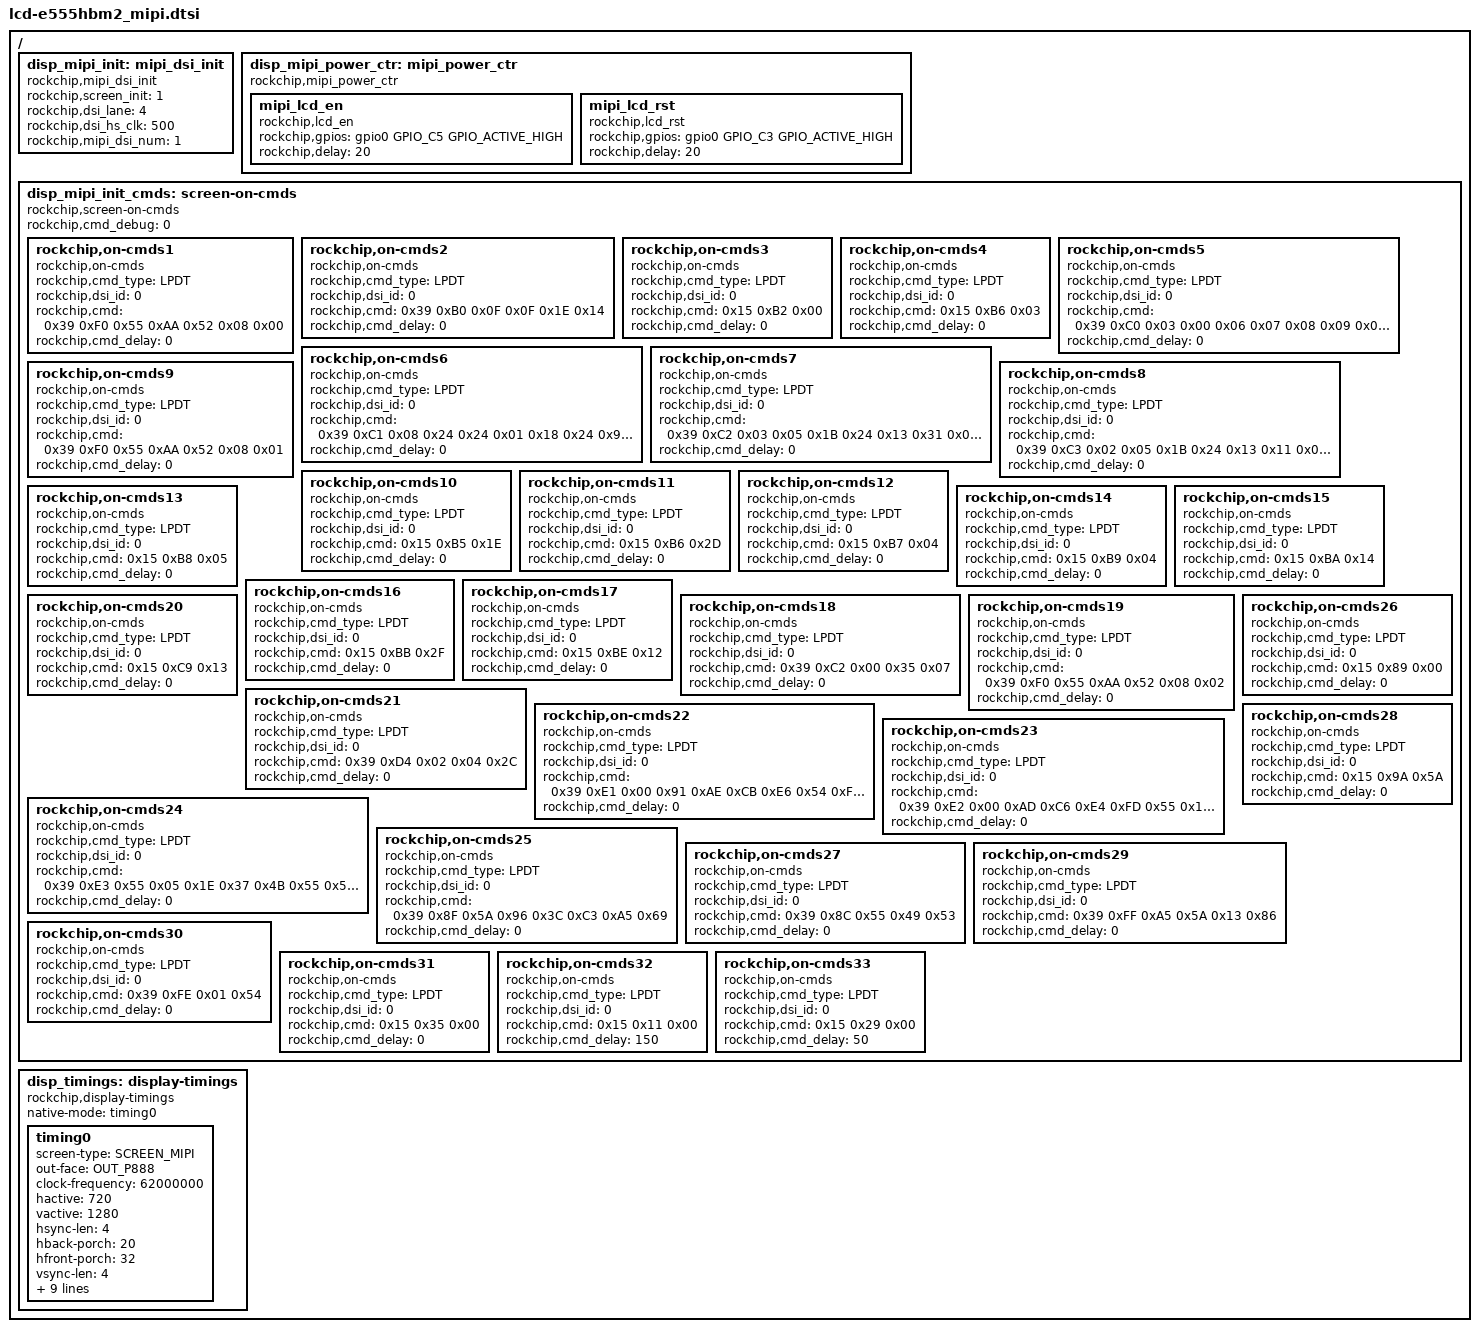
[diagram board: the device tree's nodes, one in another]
/*
 * Copyright (c) 2016 Fuzhou Rockchip Electronics Co., Ltd
 *
 * This file is dual-licensed: you can use it either under the terms
 * of the GPL or the X11 license, at your option. Note that this dual
 * licensing only applies to this file, and not this project as a
 * whole.
 *
 *  a) This file is free software; you can redistribute it and/or
 *     modify it under the terms of the GNU General Public License as
 *     published by the Free Software Foundation; either version 2 of the
 *     License, or (at your option) any later version.
 *
 *     This file is distributed in the hope that it will be useful,
 *     but WITHOUT ANY WARRANTY; without even the implied warranty of
 *     MERCHANTABILITY or FITNESS FOR A PARTICULAR PURPOSE.  See the
 *     GNU General Public License for more details.
 *
 * Or, alternatively,
 *
 *  b) Permission is hereby granted, free of charge, to any person
 *     obtaining a copy of this software and associated documentation
 *     files (the "Software"), to deal in the Software without
 *     restriction, including without limitation the rights to use,
 *     copy, modify, merge, publish, distribute, sublicense, and/or
 *     sell copies of the Software, and to permit persons to whom the
 *     Software is furnished to do so, subject to the following
 *     conditions:
 *
 *     The above copyright notice and this permission notice shall be
 *     included in all copies or substantial portions of the Software.
 *
 *     THE SOFTWARE IS PROVIDED "AS IS", WITHOUT WARRANTY OF ANY KIND,
 *     EXPRESS OR IMPLIED, INCLUDING BUT NOT LIMITED TO THE WARRANTIES
 *     OF MERCHANTABILITY, FITNESS FOR A PARTICULAR PURPOSE AND
 *     NONINFRINGEMENT. IN NO EVENT SHALL THE AUTHORS OR COPYRIGHT
 *     HOLDERS BE LIABLE FOR ANY CLAIM, DAMAGES OR OTHER LIABILITY,
 *     WHETHER IN AN ACTION OF CONTRACT, TORT OR OTHERWISE, ARISING
 *     FROM, OUT OF OR IN CONNECTION WITH THE SOFTWARE OR THE USE OR
 *     OTHER DEALINGS IN THE SOFTWARE.
 *
 * arch/arm/boot/dts/lcd_e555hbm2_mipi.dtsi
 * author: linjh@rock-chips.com
 * create date: 2016-10-26
 * lcd model: e555hbm2
 * resolution: 720 * 1280
 * mipi channel: single
 */

/ {
	/* about mipi */
	disp_mipi_init: mipi_dsi_init{
		compatible = "rockchip,mipi_dsi_init";
		rockchip,screen_init	= <1>;
		rockchip,dsi_lane	= <4>;
		rockchip,dsi_hs_clk	= <500>;
		rockchip,mipi_dsi_num	= <1>;
	};

	disp_mipi_power_ctr: mipi_power_ctr {
		compatible = "rockchip,mipi_power_ctr";
		mipi_lcd_en: mipi_lcd_en{
			compatible = "rockchip,lcd_en";
			rockchip,gpios = <&gpio0 GPIO_C5 GPIO_ACTIVE_HIGH>;
			rockchip,delay = <20>;
		};
		mipi_lcd_rst: mipi_lcd_rst{
			compatible = "rockchip,lcd_rst";
			rockchip,gpios = <&gpio0 GPIO_C3 GPIO_ACTIVE_HIGH>;
			rockchip,delay = <20>;
		};
	};

	disp_mipi_init_cmds: screen-on-cmds {
		rockchip,cmd_debug = <0>;
		compatible = "rockchip,screen-on-cmds";
		rockchip,on-cmds1 {
			compatible = "rockchip,on-cmds";
			rockchip,cmd_type = <LPDT>;
			rockchip,dsi_id = <0>;
			rockchip,cmd = <0x39 0xF0 0x55 0xAA 0x52 0x08 0x00>;
			rockchip,cmd_delay = <0>;
		};
		rockchip,on-cmds2 {
			compatible = "rockchip,on-cmds";
			rockchip,cmd_type = <LPDT>;
			rockchip,dsi_id = <0>;
			rockchip,cmd = <0x39 0xB0 0x0F 0x0F 0x1E 0x14>;
			rockchip,cmd_delay = <0>;
		};
		rockchip,on-cmds3 {
			compatible = "rockchip,on-cmds";
			rockchip,cmd_type = <LPDT>;
			rockchip,dsi_id = <0>;
			rockchip,cmd = <0x15 0xB2 0x00>;
			rockchip,cmd_delay = <0>;
		};
		rockchip,on-cmds4 {
			compatible = "rockchip,on-cmds";
			rockchip,cmd_type = <LPDT>;
			rockchip,dsi_id = <0>;
			rockchip,cmd = <0x15 0xB6 0x03>;
			rockchip,cmd_delay = <0>;
		};
		rockchip,on-cmds5 {
			compatible = "rockchip,on-cmds";
			rockchip,cmd_type = <LPDT>;
			rockchip,dsi_id = <0>;
			rockchip,cmd = <0x39 0xC0 0x03 0x00 0x06 0x07 0x08 0x09 0x00 0x00 0x00 0x00 0x02 0x00 0x0A 0x0B 0x0C 0x0D 0x00 0x00 0x00 0x00>;
			rockchip,cmd_delay = <0>;
		};
		rockchip,on-cmds6 {
			compatible = "rockchip,on-cmds";
			rockchip,cmd_type = <LPDT>;
			rockchip,dsi_id = <0>;
			rockchip,cmd = <0x39 0xC1 0x08 0x24 0x24 0x01 0x18 0x24 0x9F 0x85 0x08 0x24 0x24 0x01 0x18 0x24 0x95 0x85>;
			rockchip,cmd_delay = <0>;
		};
		rockchip,on-cmds7 {
			compatible = "rockchip,on-cmds";
			rockchip,cmd_type = <LPDT>;
			rockchip,dsi_id = <0>;
			rockchip,cmd = <0x39 0xC2 0x03 0x05 0x1B 0x24 0x13 0x31 0x01 0x05 0x1B 0x24 0x13 0x31 0x03 0x05 0x1B 0x38 0x00 0x11 0x02 0x05 0x1B 0x38 0x00 0x11>;
			rockchip,cmd_delay = <0>;
		};
		rockchip,on-cmds8 {
			compatible = "rockchip,on-cmds";
			rockchip,cmd_type = <LPDT>;
			rockchip,dsi_id = <0>;
			rockchip,cmd = <0x39 0xC3 0x02 0x05 0x1B 0x24 0x13 0x11 0x03 0x05 0x1B 0x24 0x13 0x11 0x03 0x05 0x1B 0x38 0x00 0x11 0x02 0x05 0x1B 0x38 0x00 0x11>;
			rockchip,cmd_delay = <0>;
		};
		rockchip,on-cmds9 {
			compatible = "rockchip,on-cmds";
			rockchip,cmd_type = <LPDT>;
			rockchip,dsi_id = <0>;
			rockchip,cmd = <0x39 0xF0 0x55 0xAA 0x52 0x08 0x01>;
			rockchip,cmd_delay = <0>;
		};
		rockchip,on-cmds10 {
			compatible = "rockchip,on-cmds";
			rockchip,cmd_type = <LPDT>;
			rockchip,dsi_id = <0>;
			rockchip,cmd = <0x15 0xB5 0x1E>;
			rockchip,cmd_delay = <0>;
		};
		rockchip,on-cmds11 {
			compatible = "rockchip,on-cmds";
			rockchip,cmd_type = <LPDT>;
			rockchip,dsi_id = <0>;
			rockchip,cmd = <0x15 0xB6 0x2D>;
			rockchip,cmd_delay = <0>;
		};
		rockchip,on-cmds12 {
			compatible = "rockchip,on-cmds";
			rockchip,cmd_type = <LPDT>;
			rockchip,dsi_id = <0>;
			rockchip,cmd = <0x15 0xB7 0x04>;
			rockchip,cmd_delay = <0>;
		};
		rockchip,on-cmds13 {
			compatible = "rockchip,on-cmds";
			rockchip,cmd_type = <LPDT>;
			rockchip,dsi_id = <0>;
			rockchip,cmd = <0x15 0xB8 0x05>;
			rockchip,cmd_delay = <0>;
		};
		rockchip,on-cmds14 {
			compatible = "rockchip,on-cmds";
			rockchip,cmd_type = <LPDT>;
			rockchip,dsi_id = <0>;
			rockchip,cmd = <0x15 0xB9 0x04>;
			rockchip,cmd_delay = <0>;
		};
		rockchip,on-cmds15 {
			compatible = "rockchip,on-cmds";
			rockchip,cmd_type = <LPDT>;
			rockchip,dsi_id = <0>;
			rockchip,cmd = <0x15 0xBA 0x14>;
			rockchip,cmd_delay = <0>;
		};
		rockchip,on-cmds16 {
			compatible = "rockchip,on-cmds";
			rockchip,cmd_type = <LPDT>;
			rockchip,dsi_id = <0>;
			rockchip,cmd = <0x15 0xBB 0x2F>;
			rockchip,cmd_delay = <0>;
		};
		rockchip,on-cmds17 {
			compatible = "rockchip,on-cmds";
			rockchip,cmd_type = <LPDT>;
			rockchip,dsi_id = <0>;
			rockchip,cmd = <0x15 0xBE 0x12>;
			rockchip,cmd_delay = <0>;
		};
		rockchip,on-cmds18 {
			compatible = "rockchip,on-cmds";
			rockchip,cmd_type = <LPDT>;
			rockchip,dsi_id = <0>;
			rockchip,cmd = <0x39 0xC2 0x00 0x35 0x07>;
			rockchip,cmd_delay = <0>;
		};
		rockchip,on-cmds19 {
			compatible = "rockchip,on-cmds";
			rockchip,cmd_type = <LPDT>;
			rockchip,dsi_id = <0>;
			rockchip,cmd = <0x39 0xF0 0x55 0xAA 0x52 0x08 0x02>;
			rockchip,cmd_delay = <0>;
		};
		rockchip,on-cmds20 {
			compatible = "rockchip,on-cmds";
			rockchip,cmd_type = <LPDT>;
			rockchip,dsi_id = <0>;
			rockchip,cmd = <0x15 0xC9 0x13>;
			rockchip,cmd_delay = <0>;
		};
		rockchip,on-cmds21 {
			compatible = "rockchip,on-cmds";
			rockchip,cmd_type = <LPDT>;
			rockchip,dsi_id = <0>;
			rockchip,cmd = <0x39 0xD4 0x02 0x04 0x2C>;
			rockchip,cmd_delay = <0>;
		};
		rockchip,on-cmds22 {
			compatible = "rockchip,on-cmds";
			rockchip,cmd_type = <LPDT>;
			rockchip,dsi_id = <0>;
			rockchip,cmd = <0x39 0xE1 0x00 0x91 0xAE 0xCB 0xE6
					0x54 0xFF 0x1e 0x33 0x43 0x55 0x4F
					0x66 0x78 0x8B 0x55 0x9D 0xAC 0xC0
					0xCF 0x55 0xE0 0xe8 0xF2 0xFB 0xAA
					0x03 0x0D 0x15 0x1F 0xAA 0x27 0x2C
					0x31 0x34>;
			rockchip,cmd_delay = <0>;
		};
		rockchip,on-cmds23 {
			compatible = "rockchip,on-cmds";
			rockchip,cmd_type = <LPDT>;
			rockchip,dsi_id = <0>;
			rockchip,cmd = <0x39 0xE2 0x00 0xAD 0xC6 0xE4 0xFD
					0x55 0x11 0x2A 0x3B 0x49 0x55 0x54
					0x6B 0x7C 0x8F 0x55 0xA1 0xAF 0xC3
					0xD1 0x55 0xE2 0xEA 0xF3 0xFC 0xAA
					0x04 0x0E 0x15 0x20 0xAA 0x28 0x2D
					0x32 0x35>;
			rockchip,cmd_delay = <0>;
		};
		rockchip,on-cmds24 {
			compatible = "rockchip,on-cmds";
			rockchip,cmd_type = <LPDT>;
			rockchip,dsi_id = <0>;
			rockchip,cmd = <0x39 0xE3 0x55 0x05 0x1E 0x37 0x4B
					0x55 0x5A 0x64 0x72 0x7F 0x55 0x8B
					0xA3 0xB8 0xD1 0xA5 0xE4 0xF6 0x0E
					0x23 0xAA 0x39 0x42 0x4F 0x59 0xAA
					0x64 0x70 0x7A 0x86 0xAA 0x90 0x96
					0x9C 0x9F>;
			rockchip,cmd_delay = <0>;
		};
		rockchip,on-cmds25 {
			compatible = "rockchip,on-cmds";
			rockchip,cmd_type = <LPDT>;
			rockchip,dsi_id = <0>;
			rockchip,cmd = <0x39 0x8F 0x5A 0x96 0x3C 0xC3 0xA5 0x69>;
			rockchip,cmd_delay = <0>;
		};
		rockchip,on-cmds26 {
			compatible = "rockchip,on-cmds";
			rockchip,cmd_type = <LPDT>;
			rockchip,dsi_id = <0>;
			rockchip,cmd = <0x15 0x89 0x00>;
			rockchip,cmd_delay = <0>;
		};
		rockchip,on-cmds27 {
			compatible = "rockchip,on-cmds";
			rockchip,cmd_type = <LPDT>;
			rockchip,dsi_id = <0>;
			rockchip,cmd = <0x39 0x8C 0x55 0x49 0x53>;
			rockchip,cmd_delay = <0>;
		};
		rockchip,on-cmds28 {
			compatible = "rockchip,on-cmds";
			rockchip,cmd_type = <LPDT>;
			rockchip,dsi_id = <0>;
			rockchip,cmd = <0x15 0x9A 0x5A>;
			rockchip,cmd_delay = <0>;
		};
		rockchip,on-cmds29 {
			compatible = "rockchip,on-cmds";
			rockchip,cmd_type = <LPDT>;
			rockchip,dsi_id = <0>;
			rockchip,cmd = <0x39 0xFF 0xA5 0x5A 0x13 0x86>;
			rockchip,cmd_delay = <0>;
		};
		rockchip,on-cmds30 {
			compatible = "rockchip,on-cmds";
			rockchip,cmd_type = <LPDT>;
			rockchip,dsi_id = <0>;
			rockchip,cmd = <0x39 0xFE 0x01 0x54>;
			rockchip,cmd_delay = <0>;
		};
		rockchip,on-cmds31 {
			compatible = "rockchip,on-cmds";
			rockchip,cmd_type = <LPDT>;
			rockchip,dsi_id = <0>;
			rockchip,cmd = <0x15 0x35 0x00>;
			rockchip,cmd_delay = <0>;
		};
		rockchip,on-cmds32 {
			compatible = "rockchip,on-cmds";
			rockchip,cmd_type = <LPDT>;
			rockchip,dsi_id = <0>;
			rockchip,cmd = <0x15 0x11 0x00>;
			rockchip,cmd_delay = <150>;
		};
		rockchip,on-cmds33 {
			compatible = "rockchip,on-cmds";
			rockchip,cmd_type = <LPDT>;
			rockchip,dsi_id = <0>;
			rockchip,cmd = <0x15 0x29 0x00>;
			rockchip,cmd_delay = <50>;
		};
	};

	disp_timings: display-timings {
		native-mode = <&timing0>;
		compatible = "rockchip,display-timings";
		timing0: timing0 {
			screen-type = <SCREEN_MIPI>;
			/*lvds-format = <LVDS_8BIT_2>;*/
			out-face    = <OUT_P888>;
			clock-frequency = <62000000>;
			hactive = <720>;
			vactive = <1280>;
			hsync-len = <4>;
			hback-porch = <20>;
			hfront-porch = <32>;
			vsync-len = <4>;
			vback-porch = <15>;
			vfront-porch = <15>;
			hsync-active = <0>;
			vsync-active = <0>;
			de-active = <0>;
			pixelclk-active = <0>;
			swap-rb = <0>;
			swap-rg = <0>;
			swap-gb = <0>;
		};
	};
};
